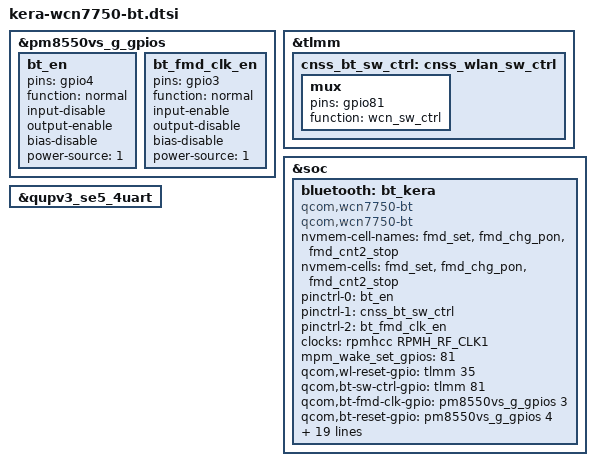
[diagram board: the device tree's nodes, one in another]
// SPDX-License-Identifier: BSD-3-Clause

/*
 * Copyright (c) 2024 Qualcomm Innovation Center, Inc. All rights reserved.
 */

#include <dt-bindings/interrupt-controller/arm-gic.h>
#include <dt-bindings/interconnect/qcom,kera.h>
#include <dt-bindings/clock/qcom,rpmh.h>

&pm8550vs_g_gpios {
	bt_en: bt_en {
		pins = "gpio4";
		function = "normal";
		input-disable;
		output-enable;
		bias-disable;
		power-source = <1>;
	};
	bt_fmd_clk_en: bt_fmd_clk_en {
		pins = "gpio3";
		function = "normal";
		input-enable;
		output-disable;
		bias-disable;
		power-source = <1>;
	};
};

&tlmm {
	cnss_bt_sw_ctrl: cnss_wlan_sw_ctrl {
		mux {
			pins = "gpio81";
			function = "wcn_sw_ctrl";
		};
	};
};

&soc {
	bluetooth: bt_kera {
		compatible = "qcom,wcn7750-bt";
		qcom,wcn7750-bt;

		nvmem-cell-names = "fmd_set", "fmd_chg_pon", "fmd_cnt2_stop";
		nvmem-cells = <&fmd_set>, <&fmd_chg_pon>, <&fmd_cnt2_stop>;

		pinctrl-names = "bt_en", "sw_ctrl", "bt_fmd_clk_en";
		pinctrl-0 = <&bt_en>;
		pinctrl-1 = <&cnss_bt_sw_ctrl>;
		pinctrl-2 = <&bt_fmd_clk_en>;

		clock-names = "bt_rf_clk1";
		clocks = <&rpmhcc RPMH_RF_CLK1>;

		mpm_wake_set_gpios   = <81>;
		qcom,wl-reset-gpio   = <&tlmm 35 0>; /* WCN_WIFI_EN */
		qcom,bt-sw-ctrl-gpio = <&tlmm 81 0>; /* WCN_SW_CTRL */
		qcom,bt-fmd-clk-gpio = <&pm8550vs_g_gpios 3 0>; /* FMD_CLK_EN */
		qcom,bt-reset-gpio   = <&pm8550vs_g_gpios 4 0>; /* WCN_BT_EN */

		qcom,bt-vdd-io-supply      = <&L7B>; /* WCN_1P8_IO */
		qcom,bt-vdd-aon-supply     = <&L11B>; /* AON LDO */
		qcom,bt-vdd-rfacmn-supply  = <&S3B>; /* RF 0p8/CMN */
		qcom,bt-vdd-dig-supply     = <&S3B>; /* BT LDO/BT_CX_MX */
		qcom,bt-vdd-rfa-0p8-supply = <&L6K>; /* RFA 0p8 / AV91C_VDD */
		qcom,bt-vdd-rfa1-supply    = <&S1B>; /* RFA 1p7 */
		qcom,bt-vdd-rfa2-supply    = <&S2B>; /* RFA 1p2 */
		qcom,bt-vdd-ipa-2p2-supply = <&S4B>; /* WCN_2p2_RFA */

		qcom,bt-vdd-io-config      = <1620000 1800000 0 1 1>;
		qcom,bt-vdd-aon-config     = <1800000 1800000 0 1 1>;
		qcom,bt-vdd-rfacmn-config  = <880000 2736000 0 1 1>;
		qcom,bt-vdd-dig-config     = <880000 2736000 0 1 1>;
		qcom,bt-vdd-rfa-0p8-config = <900000 2000000 0 1 1>;
		qcom,bt-vdd-rfa1-config    = <1856000 2044000 0 1 1>;
		qcom,bt-vdd-rfa2-config    = <1256000 2092000 0 1 1>;
		qcom,bt-vdd-ipa-2p2-config = <2156000 2700000 0 1 1>;
	};
};

//uart instance
&qupv3_se5_4uart {
	status = "ok";
};
